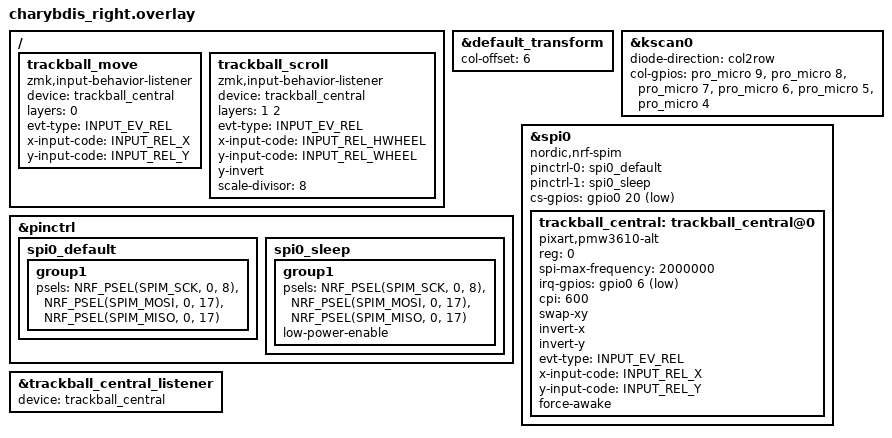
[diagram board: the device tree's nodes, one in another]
/*
 * Copyright (c) 2022 Duccio Breschi
 *
 * SPDX-License-Identifier: MIT
 */

#include "charybdis.dtsi"
#include <zephyr/dt-bindings/input/input-event-codes.h>

&default_transform {
    col-offset = <6>;
};

&kscan0 {
    diode-direction = "col2row";
    col-gpios
        = <&pro_micro 9 (GPIO_ACTIVE_HIGH)> // COL0
        , <&pro_micro 8 (GPIO_ACTIVE_HIGH)> // COL1
        , <&pro_micro 7 (GPIO_ACTIVE_HIGH)> // COL2
        , <&pro_micro 6 (GPIO_ACTIVE_HIGH)> // COL3
	    , <&pro_micro 5 (GPIO_ACTIVE_HIGH)> // COL4
        , <&pro_micro 4 (GPIO_ACTIVE_HIGH)> // COL5
    ;
};

&pinctrl {
    spi0_default: spi0_default {
        group1 {
            psels = <NRF_PSEL(SPIM_SCK, 0, 8)>,
                <NRF_PSEL(SPIM_MOSI, 0, 17)>,
                <NRF_PSEL(SPIM_MISO, 0, 17)>;
        };
    };

    spi0_sleep: spi0_sleep {
        group1 {
            psels = <NRF_PSEL(SPIM_SCK, 0, 8)>,
                <NRF_PSEL(SPIM_MOSI, 0, 17)>,
                <NRF_PSEL(SPIM_MISO, 0, 17)>;
            low-power-enable;
        };
    };
};

&spi0 {
    status = "okay";
    compatible = "nordic,nrf-spim";
    pinctrl-0 = <&spi0_default>;
    pinctrl-1 = <&spi0_sleep>;
    pinctrl-names = "default", "sleep";
    cs-gpios = <&gpio0 20 GPIO_ACTIVE_LOW>;

    trackball_central: trackball_central@0 {
        status = "okay";
        compatible = "pixart,pmw3610-alt";
        reg = <0>;
        spi-max-frequency = <2000000>;
        irq-gpios = <&gpio0 6 (GPIO_ACTIVE_LOW | GPIO_PULL_UP)>;
        cpi = <600>;
        swap-xy;
        invert-x;
        invert-y;
        evt-type = <INPUT_EV_REL>;
        x-input-code = <INPUT_REL_X>;
        y-input-code = <INPUT_REL_Y>;
        force-awake;
    };
};

// Enable the trackball listener
&trackball_central_listener {
    status = "okay";
    device = <&trackball_central>;
};

/ {
    // Trackball movement on default layer (layer 0)
    trackball_move: trackball_move {
        compatible = "zmk,input-behavior-listener";
        device = <&trackball_central>;
        layers = <0>;
        evt-type = <INPUT_EV_REL>;
        x-input-code = <INPUT_REL_X>;
        y-input-code = <INPUT_REL_Y>;
    };

    // Trackball scroll on layers 1 and 2 (Raise/Lower)
    trackball_scroll: trackball_scroll {
        compatible = "zmk,input-behavior-listener";
        device = <&trackball_central>;
        layers = <1 2>;
        evt-type = <INPUT_EV_REL>;
        x-input-code = <INPUT_REL_HWHEEL>;
        y-input-code = <INPUT_REL_WHEEL>;
        y-invert;
        scale-divisor = <8>;
    };
};
